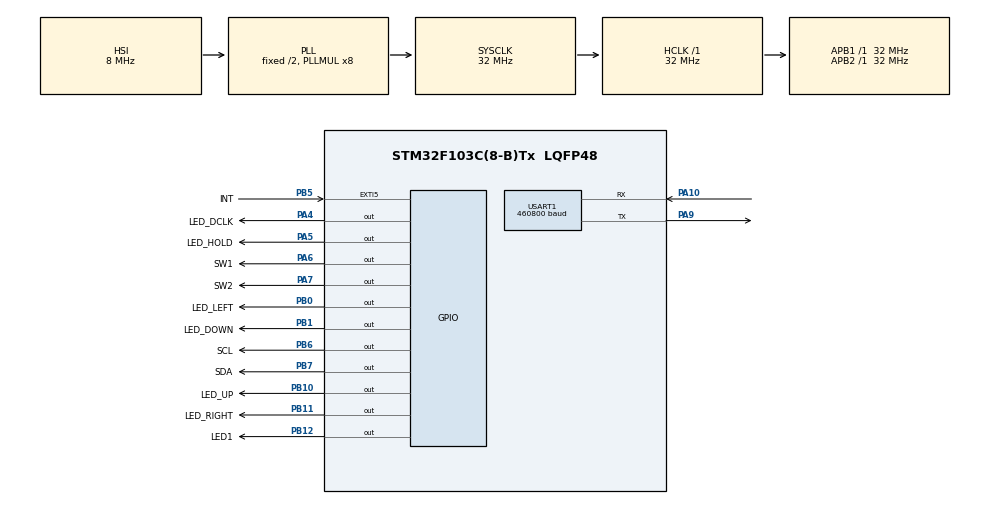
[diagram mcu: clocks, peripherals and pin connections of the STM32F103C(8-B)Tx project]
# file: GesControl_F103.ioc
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Mcu.Family=STM32F1
Mcu.Name=STM32F103C(8-B)Tx
Mcu.Package=LQFP48
NVIC.EXTI9_5_IRQn=true\:0\:0\:false\:false\:true
NVIC.PriorityGroup=NVIC_PRIORITYGROUP_4
PA10.Mode=Asynchronous
PA10.Signal=USART1_RX
PA13.Mode=Serial_Wire
PA13.Signal=SYS_JTMS-SWDIO
PA14.Mode=Serial_Wire
PA14.Signal=SYS_JTCK-SWCLK
PA4.GPIO_Label=LED_DCLK
PA4.Signal=GPIO_Output
PA5.GPIO_Label=LED_HOLD
PA5.Signal=GPIO_Output
PA6.GPIO_Label=SW1
PA6.Signal=GPIO_Output
PA7.GPIO_Label=SW2
PA7.Signal=GPIO_Output
PA9.Mode=Asynchronous
PA9.Signal=USART1_TX
PB0.GPIO_Label=LED_LEFT
PB0.Signal=GPIO_Output
PB1.GPIO_Label=LED_DOWN
PB1.Signal=GPIO_Output
PB10.GPIO_Label=LED_UP
PB10.Signal=GPIO_Output
PB11.GPIO_Label=LED_RIGHT
PB11.Signal=GPIO_Output
PB12.GPIO_Label=LED1
PB12.Signal=GPIO_Output
PB5.GPIO_Label=INT
PB5.GPIO_ModeDefaultEXTI=GPIO_MODE_IT_FALLING
PB5.Signal=GPXTI5
PB6.GPIO_Label=SCL
PB6.GPIO_ModeDefaultOutputPP=GPIO_MODE_OUTPUT_OD
PB6.GPIO_Speed=GPIO_SPEED_FREQ_HIGH
PB6.Signal=GPIO_Output
PB7.GPIO_Label=SDA
PB7.GPIO_ModeDefaultOutputPP=GPIO_MODE_OUTPUT_OD
PB7.GPIO_Speed=GPIO_SPEED_FREQ_HIGH
PB7.Signal=GPIO_Output
ProjectManager.HeapSize=0x200
ProjectManager.StackSize=0x400
ProjectManager.TargetToolchain=MDK-ARM V5
RCC.AHBFreq_Value=32000000
RCC.APB1Freq_Value=32000000
RCC.APB1TimFreq_Value=32000000
RCC.APB2Freq_Value=32000000
RCC.APB2TimFreq_Value=32000000
RCC.HCLKFreq_Value=32000000
RCC.PLLMUL=RCC_PLL_MUL8
RCC.SYSCLKFreq_VALUE=32000000
RCC.SYSCLKSource=RCC_SYSCLKSOURCE_PLLCLK
RCC.USBFreq_Value=32000000
USART1.BaudRate=460800
USART1.VirtualMode=VM_ASYNC
board=GesControl_F103

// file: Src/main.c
/**
  ******************************************************************************
  * File Name          : main.c
  * Description        : Main program body
  ******************************************************************************
  *
  * COPYRIGHT(c) 2019 STMicroelectronics
  *
  * Redistribution and use in source and binary forms, with or without modification,
  * are permitted provided that the following conditions are met:
  *   1. Redistributions of source code must retain the above copyright notice,
  *      this list of conditions and the following disclaimer.
  *   2. Redistributions in binary form must reproduce the above copyright notice,
  *      this list of conditions and the following disclaimer in the documentation
  *      and/or other materials provided with the distribution.
  *   3. Neither the name of STMicroelectronics nor the names of its contributors
  *      may be used to endorse or promote products derived from this software
  *      without specific prior written permission.
  *
  * THIS SOFTWARE IS PROVIDED BY THE COPYRIGHT HOLDERS AND CONTRIBUTORS "AS IS"
  * AND ANY EXPRESS OR IMPLIED WARRANTIES, INCLUDING, BUT NOT LIMITED TO, THE
  * IMPLIED WARRANTIES OF MERCHANTABILITY AND FITNESS FOR A PARTICULAR PURPOSE ARE
  * DISCLAIMED. IN NO EVENT SHALL THE COPYRIGHT HOLDER OR CONTRIBUTORS BE LIABLE
  * FOR ANY DIRECT, INDIRECT, INCIDENTAL, SPECIAL, EXEMPLARY, OR CONSEQUENTIAL
  * DAMAGES (INCLUDING, BUT NOT LIMITED TO, PROCUREMENT OF SUBSTITUTE GOODS OR
  * SERVICES; LOSS OF USE, DATA, OR PROFITS; OR BUSINESS INTERRUPTION) HOWEVER
  * CAUSED AND ON ANY THEORY OF LIABILITY, WHETHER IN CONTRACT, STRICT LIABILITY,
  * OR TORT (INCLUDING NEGLIGENCE OR OTHERWISE) ARISING IN ANY WAY OUT OF THE USE
  * OF THIS SOFTWARE, EVEN IF ADVISED OF THE POSSIBILITY OF SUCH DAMAGE.
  *
  ******************************************************************************
  */
#include "main.h"
#include "stm32f1xx_hal.h"

/* USER CODE BEGIN Includes */
#include "App.h"

/* USER CODE END Includes */

UART_HandleTypeDef huart1;

/* USER CODE BEGIN PV */
/* Private variables ---------------------------------------------------------*/
#define DEBUG_UART          huart1

/* USER CODE END PV */

void SystemClock_Config(void);
void Error_Handler(void);
static void MX_GPIO_Init(void);
static void MX_USART1_UART_Init(void);

/* USER CODE BEGIN PFP */
/* Private function prototypes -----------------------------------------------*/

/* USER CODE END PFP */

int main(void)
{

  /* MCU Configuration----------------------------------------------------------*/

  /* Reset of all peripherals, Initializes the Flash interface and the Systick. */
  HAL_Init();

  /* Configure the system clock */
  SystemClock_Config();

  /* Initialize all configured peripherals */
  MX_GPIO_Init();
  MX_USART1_UART_Init();

  /* USER CODE BEGIN 2 */

	App_Init();
  /* USER CODE END 2 */

  /* Infinite loop */
  /* USER CODE BEGIN WHILE */
  while (1)
  {
	  App_Task();
  /* USER CODE END WHILE */

  }

}

/** System Clock Configuration
*/
void SystemClock_Config(void)
{

  RCC_OscInitTypeDef RCC_OscInitStruct;
  RCC_ClkInitTypeDef RCC_ClkInitStruct;

    /**Initializes the CPU, AHB and APB busses clocks
    */
  RCC_OscInitStruct.OscillatorType = RCC_OSCILLATORTYPE_HSI;
  RCC_OscInitStruct.HSIState = RCC_HSI_ON;
  RCC_OscInitStruct.HSICalibrationValue = 16;
  RCC_OscInitStruct.PLL.PLLState = RCC_PLL_ON;
  RCC_OscInitStruct.PLL.PLLSource = RCC_PLLSOURCE_HSI_DIV2;
  RCC_OscInitStruct.PLL.PLLMUL = RCC_PLL_MUL8;
  if (HAL_RCC_OscConfig(&RCC_OscInitStruct) != HAL_OK)
  {
    Error_Handler();
  }

    /**Initializes the CPU, AHB and APB busses clocks
    */
  RCC_ClkInitStruct.ClockType = RCC_CLOCKTYPE_HCLK|RCC_CLOCKTYPE_SYSCLK
                              |RCC_CLOCKTYPE_PCLK1|RCC_CLOCKTYPE_PCLK2;
  RCC_ClkInitStruct.SYSCLKSource = RCC_SYSCLKSOURCE_PLLCLK;
  RCC_ClkInitStruct.AHBCLKDivider = RCC_SYSCLK_DIV1;
  RCC_ClkInitStruct.APB1CLKDivider = RCC_HCLK_DIV1;
  RCC_ClkInitStruct.APB2CLKDivider = RCC_HCLK_DIV1;

  if (HAL_RCC_ClockConfig(&RCC_ClkInitStruct, FLASH_LATENCY_1) != HAL_OK)
  {
    Error_Handler();
  }

    /**Configure the Systick interrupt time
    */
  HAL_SYSTICK_Config(HAL_RCC_GetHCLKFreq()/1000);

    /**Configure the Systick
    */
  HAL_SYSTICK_CLKSourceConfig(SYSTICK_CLKSOURCE_HCLK);

  /* SysTick_IRQn interrupt configuration */
  HAL_NVIC_SetPriority(SysTick_IRQn, 0, 0);
}

/* USART1 init function */
static void MX_USART1_UART_Init(void)
{

  huart1.Instance = USART1;
  huart1.Init.BaudRate = 460800;
  huart1.Init.WordLength = UART_WORDLENGTH_8B;
  huart1.Init.StopBits = UART_STOPBITS_1;
  huart1.Init.Parity = UART_PARITY_NONE;
  huart1.Init.Mode = UART_MODE_TX_RX;
  huart1.Init.HwFlowCtl = UART_HWCONTROL_NONE;
  huart1.Init.OverSampling = UART_OVERSAMPLING_16;
  if (HAL_UART_Init(&huart1) != HAL_OK)
  {
    Error_Handler();
  }

}

/** Configure pins as
        * Analog
        * Input
        * Output
        * EVENT_OUT
        * EXTI
*/
static void MX_GPIO_Init(void)
{

  GPIO_InitTypeDef GPIO_InitStruct;

  /* GPIO Ports Clock Enable */
  __HAL_RCC_GPIOA_CLK_ENABLE();
  __HAL_RCC_GPIOB_CLK_ENABLE();

  /*Configure GPIO pin Output Level */
  HAL_GPIO_WritePin(GPIOA, LED_DCLK_Pin|LED_HOLD_Pin|SW1_Pin|SW2_Pin, GPIO_PIN_RESET);

  /*Configure GPIO pin Output Level */
  HAL_GPIO_WritePin(GPIOB, LED_LEFT_Pin|LED_DOWN_Pin|LED_UP_Pin|LED_RIGHT_Pin
                          |LED1_Pin|SCL_Pin|SDA_Pin, GPIO_PIN_RESET);

  /*Configure GPIO pins : LED_DCLK_Pin LED_HOLD_Pin SW1_Pin SW2_Pin */
  GPIO_InitStruct.Pin = LED_DCLK_Pin|LED_HOLD_Pin|SW1_Pin|SW2_Pin;
  GPIO_InitStruct.Mode = GPIO_MODE_OUTPUT_PP;
  GPIO_InitStruct.Speed = GPIO_SPEED_FREQ_LOW;
  HAL_GPIO_Init(GPIOA, &GPIO_InitStruct);

  /*Configure GPIO pins : LED_LEFT_Pin LED_DOWN_Pin LED_UP_Pin LED_RIGHT_Pin
                           LED1_Pin */
  GPIO_InitStruct.Pin = LED_LEFT_Pin|LED_DOWN_Pin|LED_UP_Pin|LED_RIGHT_Pin
                          |LED1_Pin;
  GPIO_InitStruct.Mode = GPIO_MODE_OUTPUT_PP;
  GPIO_InitStruct.Speed = GPIO_SPEED_FREQ_LOW;
  HAL_GPIO_Init(GPIOB, &GPIO_InitStruct);

  /*Configure GPIO pin : INT_Pin */
  GPIO_InitStruct.Pin = INT_Pin;
  GPIO_InitStruct.Mode = GPIO_MODE_IT_FALLING;
  GPIO_InitStruct.Pull = GPIO_NOPULL;
  HAL_GPIO_Init(INT_GPIO_Port, &GPIO_InitStruct);

  /*Configure GPIO pins : SCL_Pin SDA_Pin */
  GPIO_InitStruct.Pin = SCL_Pin|SDA_Pin;
  GPIO_InitStruct.Mode = GPIO_MODE_OUTPUT_OD;
  GPIO_InitStruct.Speed = GPIO_SPEED_FREQ_HIGH;
  HAL_GPIO_Init(GPIOB, &GPIO_InitStruct);

  /* EXTI interrupt init*/
  HAL_NVIC_SetPriority(EXTI9_5_IRQn, 0, 0);
  HAL_NVIC_EnableIRQ(EXTI9_5_IRQn);

}

/* USER CODE BEGIN 4 */
int fputc(int ch, FILE *f)

{
    HAL_UART_Transmit(&DEBUG_UART, (uint8_t *)&ch,1, 0xFFFF);
    return ch;
}

/* USER CODE END 4 */

void Error_Handler(void)
{
  while(1)
  {
  }
}

/************************ (C) COPYRIGHT STMicroelectronics *****END OF FILE****/
